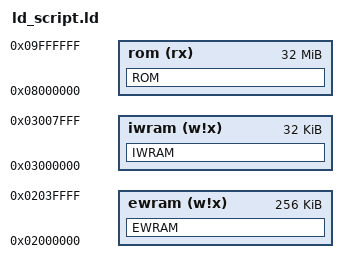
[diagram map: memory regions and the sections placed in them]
OUTPUT_ARCH(arm)

gNumMusicPlayers = 0x20;
gMaxLines = 0;

MEMORY {
    ewram (w!x) : ORIGIN = 0x02000000, LENGTH = 256K
    iwram (w!x) : ORIGIN = 0x03000000, LENGTH = 32K
    rom (rx) : ORIGIN = 0x08000000, LENGTH = 32M
}

SECTIONS
{
    EWRAM (NOLOAD) : ALIGN(4)
    {
        INCLUDE "sym_ewram.txt"
    } >ewram

    IWRAM (NOLOAD) : ALIGN(4)
    {
        INCLUDE "sym_iwram.txt"
    } >iwram

    ROM : ALIGN(2)
	{
        asm/crt0.o(.text);
        asm/code1.o(.text);
        asm/code2.o(.text);
        data/mid_data.o(.data)
        asm/code3.o(.text);
        data/data.o(.data);
    } >rom

    ROM_END = .;

    /* DWARF debug sections.
       Symbols in the DWARF debugging sections are relative to the beginning
       of the section so we begin them at 0.  */

    /* DWARF 1 */
    .debug          0 : { *(.debug) }
    .line           0 : { *(.line) }

    /* GNU DWARF 1 extensions */
    .debug_srcinfo  0 : { *(.debug_srcinfo) }
    .debug_sfnames  0 : { *(.debug_sfnames) }

    /* DWARF 1.1 and DWARF 2 */
    .debug_aranges  0 : { *(.debug_aranges) }
    .debug_pubnames 0 : { *(.debug_pubnames) }

    /* DWARF 2 */
    .debug_info     0 : { *(.debug_info .gnu.linkonce.wi.*) }
    .debug_abbrev   0 : { *(.debug_abbrev) }
    .debug_line     0 : { *(.debug_line) }
    .debug_frame    0 : { *(.debug_frame) }
    .debug_str      0 : { *(.debug_str) }
    .debug_loc      0 : { *(.debug_loc) }
    .debug_macinfo  0 : { *(.debug_macinfo) }

    /* Discard everything not specifically mentioned above. */
    /DISCARD/ :
    {
        *(*);
    }
}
